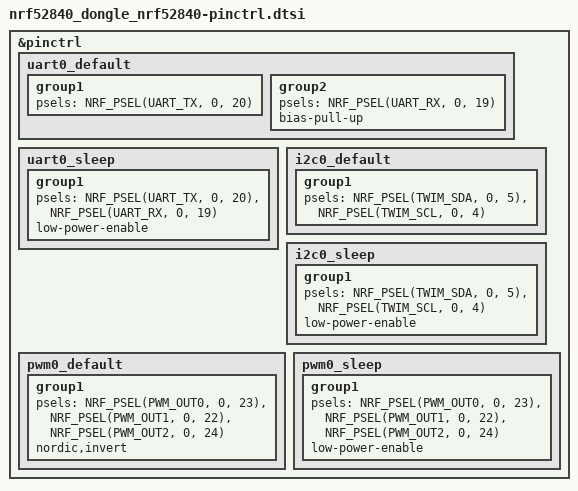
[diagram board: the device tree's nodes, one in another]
/*
 * Copyright (c) 2016-2025 Makerdiary <https://makerdiary.com>
 * SPDX-License-Identifier: Apache-2.0
 */

&pinctrl {
	uart0_default: uart0_default {
		group1 {
			psels = <NRF_PSEL(UART_TX, 0, 20)>;
		};
		group2 {
			psels = <NRF_PSEL(UART_RX, 0, 19)>;
			bias-pull-up;
		};
	};

	uart0_sleep: uart0_sleep {
		group1 {
			psels = <NRF_PSEL(UART_TX, 0, 20)>,
				<NRF_PSEL(UART_RX, 0, 19)>;
			low-power-enable;
		};
	};

	i2c0_default: i2c0_default {
		group1 {
			psels = <NRF_PSEL(TWIM_SDA, 0, 5)>,
				<NRF_PSEL(TWIM_SCL, 0, 4)>;
		};
	};

	i2c0_sleep: i2c0_sleep {
		group1 {
			psels = <NRF_PSEL(TWIM_SDA, 0, 5)>,
				<NRF_PSEL(TWIM_SCL, 0, 4)>;
			low-power-enable;
		};
	};

	pwm0_default: pwm0_default {
		group1 {
			psels = <NRF_PSEL(PWM_OUT0, 0, 23)>,
				<NRF_PSEL(PWM_OUT1, 0, 22)>,
				<NRF_PSEL(PWM_OUT2, 0, 24)>;
			nordic,invert;
		};
	};

	pwm0_sleep: pwm0_sleep {
		group1 {
			psels = <NRF_PSEL(PWM_OUT0, 0, 23)>,
				<NRF_PSEL(PWM_OUT1, 0, 22)>,
				<NRF_PSEL(PWM_OUT2, 0, 24)>;
			low-power-enable;
		};
	};
};
